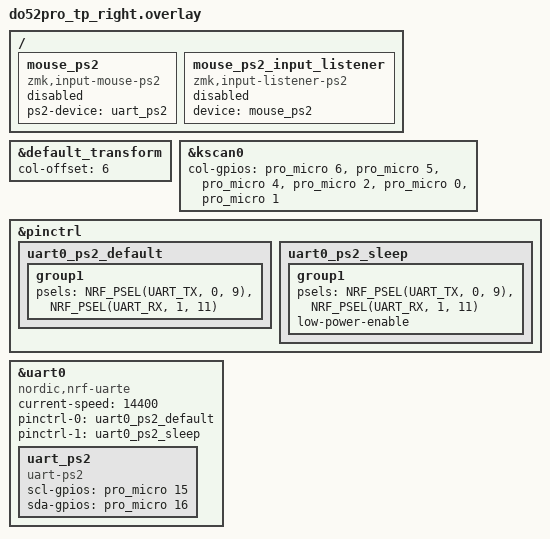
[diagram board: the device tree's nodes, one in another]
#include "do52pro_tp.dtsi"

&default_transform { col-offset = <6>; };

&kscan0 {
    col-gpios
        = <&pro_micro 6 GPIO_ACTIVE_HIGH>, <&pro_micro 5 GPIO_ACTIVE_HIGH>
        , <&pro_micro 4 GPIO_ACTIVE_HIGH>, <&pro_micro 2 GPIO_ACTIVE_HIGH>
        , <&pro_micro 0 GPIO_ACTIVE_HIGH>, <&pro_micro 1 GPIO_ACTIVE_HIGH>
        ;
};

#define MOUSE_PS2_DT_PRESENT
#define MOUSE_PS2_DRIVER_UART

&pinctrl {
    uart0_ps2_default: uart0_ps2_default {
        group1 {
            // D16 (P1.11) を UART_RX として使用（SDAのデータ読み取り用）
            // TXは未使用の空きピン（例: P0.09 など、基板上で使っていないピン）を指定
            psels = <NRF_PSEL(UART_TX, 0, 9)>, <NRF_PSEL(UART_RX, 1, 11)>;
        };
    };

    uart0_ps2_sleep: uart0_ps2_sleep {
        group1 {
            psels = <NRF_PSEL(UART_TX, 0, 9)>, <NRF_PSEL(UART_RX, 1, 11)>;
            low-power-enable;
        };
    };
};

&uart0 {
    status = "okay";
    compatible = "nordic,nrf-uarte";
    current-speed = <14400>;
    pinctrl-0 = <&uart0_ps2_default>;
    pinctrl-1 = <&uart0_ps2_sleep>;
    pinctrl-names = "default", "sleep";

    uart_ps2: uart_ps2 {
        status = "okay";
        compatible = "uart-ps2";
        scl-gpios = <&pro_micro 15 GPIO_ACTIVE_HIGH>;
        sda-gpios = <&pro_micro 16 GPIO_ACTIVE_HIGH>;
    };
};

/ {
    mouse_ps2: mouse_ps2 {
        status = "disabled";
        compatible = "zmk,input-mouse-ps2";
        ps2-device = <&uart_ps2>;
    };

    mouse_ps2_input_listener: mouse_ps2_input_listener {
        status = "disabled";
        compatible = "zmk,input-listener-ps2";
        device = <&mouse_ps2>;
    };
};
